# nrf54lm20a_enga_application register map
Vendor: Nordic Semiconductor; Series: nrf54l; File version: 1
CPU: CM33 r0p4, little endian, MPU, FPU, 3 interrupt priority bits, 270 interrupts, 4 SAU regions
Registers are 32-bit, read-write, reset 0x0 unless marked. A register's access mark holds for its fields unless they carry their own. Offsets are from the block's base; [hi:lo] are bit positions; lines under a group give offsets from that group; {n}, {i} and the like mark numbered series; 'fields as' and 'values as' point back to an identical list.

## GLOBAL_ECB00_NS — AES ECB Mode Encryption 0
Base 0x4004B000
Same registers: GLOBAL_ECB00_S 0x5004B000
0x00 TASKS_START wo — Start ECB block encrypt
  [0] TASKS_START
    1=Trigger task
0x04 TASKS_STOP wo — Abort a possible executing ECB operation
  [0] TASKS_STOP
    1=Trigger task
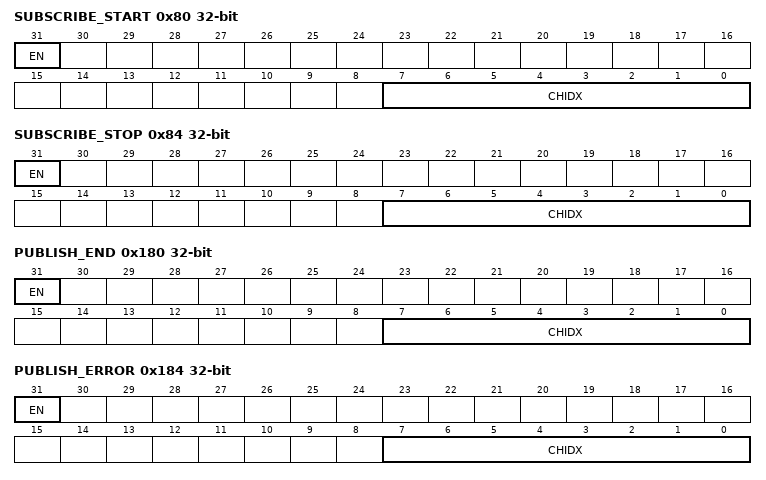
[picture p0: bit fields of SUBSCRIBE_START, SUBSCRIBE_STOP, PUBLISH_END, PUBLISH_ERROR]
0x80 SUBSCRIBE_START — Subscribe configuration for task START
  [31] EN
    0=Disabled (Disable subscription); 1=Enabled (Enable subscription)
  [7:0] CHIDX — DPPI channel that task START will subscribe to
0x84 SUBSCRIBE_STOP — Subscribe configuration for task STOP
  [31] EN
    values as SUBSCRIBE_START.EN
  [7:0] CHIDX — DPPI channel that task STOP will subscribe to
0x100 EVENTS_END — ECB block encrypt complete
  [0] EVENTS_END
    0=NotGenerated (Event not generated); 1=Generated (Event generated)
0x104 EVENTS_ERROR — ECB block encrypt aborted because of a STOP task or due to an error
  [0] EVENTS_ERROR
    values as EVENTS_END.EVENTS_END
0x180 PUBLISH_END — Publish configuration for event END
  [31] EN
    0=Disabled (Disable publishing); 1=Enabled (Enable publishing)
  [7:0] CHIDX — DPPI channel that event END will publish to
0x184 PUBLISH_ERROR — Publish configuration for event ERROR
  [31] EN
    values as PUBLISH_END.EN
  [7:0] CHIDX — DPPI channel that event ERROR will publish to
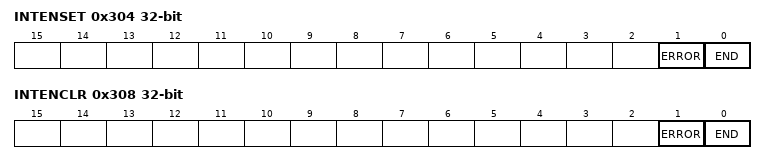
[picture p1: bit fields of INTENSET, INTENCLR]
0x304 INTENSET — Enable interrupt
  [1] ERROR — Write '1' to enable interrupt for event ERROR
    on read: 0=Disabled (Read: Disabled); 1=Enabled (Read: Enabled) | on write: 1=Set (Enable)
  [0] END — Write '1' to enable interrupt for event END
    values as ERROR
0x308 INTENCLR — Disable interrupt
  [1] ERROR — Write '1' to disable interrupt for event ERROR
    on read: 0=Disabled (Read: Disabled); 1=Enabled (Read: Enabled) | on write: 1=Clear (Disable)
  [0] END — Write '1' to disable interrupt for event END
    values as ERROR
0x400 ERRORSTATUS ro
  [2:0] ERRORSTATUS — Error status when the ERROR event is generated
    0=No errors have occurred; 1=PrematureInptrEnd (End of INPTR job list before data structure was read.); 2=PrematureOutptrEnd (End of OUTPTR job list before data structure was read.); 3=EncryptionTooSlow (Deprecated enumerator - Encryption aborted due to higher priority peripheral requesting or using the AES module.); 3=Aborted (Encryption aborted due to higher priority peripheral requesting or using the AES module.); 4=DmaError (Bus error during DMA access.)
0x510 KEY group — Unspecified
  {0x0+4j} VALUE[{j}] (j=0..3) wo — Description collection: 128-bit AES key
    [31:0] VALUE — AES 128-bit key value, bits (32*(n+1))-1 : (32*n)
0x530 IN group — IN EasyDMA channel
  0x00 PTR — Input pointer
    [31:0] PTR — Points to a job list containing unencrypted ECB data structure
0x538 OUT group — OUT EasyDMA channel
  0x00 PTR — Output pointer Points to a job list containing encrypted ECB data structure
    [31:0] PTR — Output pointer

## GLOBAL_GLITCHDET_S — Voltage glitch detectors
Base 0x5004E000
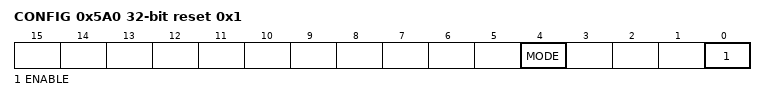
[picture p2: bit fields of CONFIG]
0x5A0 CONFIG reset 0x1 — Configuration for glitch detector
  [4] MODE — Glitch detector mode
    0=High pass filter mode; 1=Cap divider mode
  [0] ENABLE — Enable glitch detector
    0=Disable glitch detector; 1=Enable glitch detector

## GLOBAL_P2_NS — GPIO Port 0
Base 0x40050400
Same registers: GLOBAL_P1_NS 0x400D8200, GLOBAL_P3_NS 0x400D8600, GLOBAL_P0_NS 0x4010A000, GLOBAL_P2_S 0x50050400 (alternate view of GLOBAL_GPIOHSPADCTRL_S), GLOBAL_P1_S 0x500D8200, GLOBAL_P3_S 0x500D8600, GLOBAL_P0_S 0x5010A000
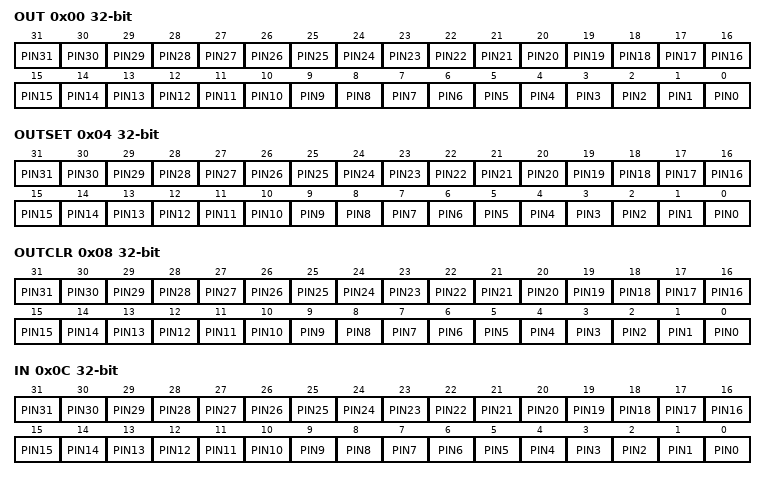
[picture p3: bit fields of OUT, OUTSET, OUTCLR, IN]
0x00 OUT — Write GPIO port
  [all] fields
    0=Low (Pin driver is low); 1=High (Pin driver is high)
  [n] PIN{n} (n=0..31)
0x04 OUTSET write-1-sets — Set individual bits in GPIO port
  [all] fields
    on read: 0=Low (Read: pin driver is low); 1=High (Read: pin driver is high) | on write: 1=Set (Write: writing a '1' sets the pin high; writing a '0' has no effect)
  [n] PIN{n} (n=0..31)
0x08 OUTCLR write-1-clears — Clear individual bits in GPIO port
  [all] fields
    on read: 0=Low (Read: pin driver is low); 1=High (Read: pin driver is high) | on write: 1=Clear (Write: writing a '1' sets the pin low; writing a '0' has no effect)
  [n] PIN{n} (n=0..31)
0x0C IN ro — Read GPIO port
  [all] fields
    0=Low (Pin input is low); 1=High (Pin input is high)
  [n] PIN{n} (n=0..31)
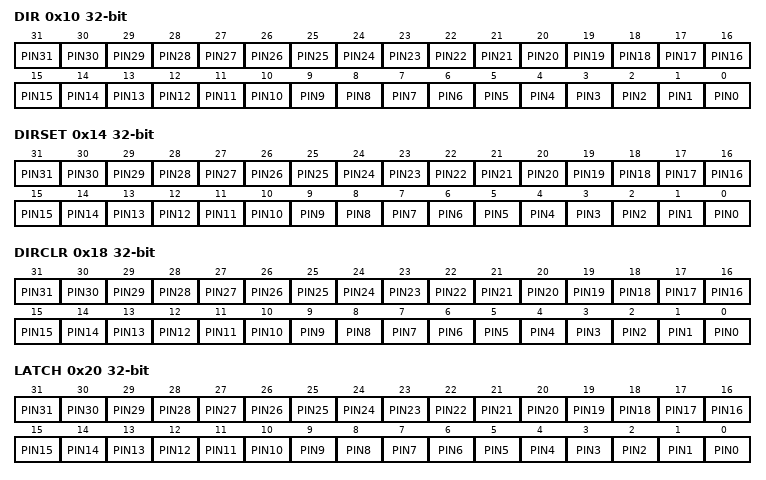
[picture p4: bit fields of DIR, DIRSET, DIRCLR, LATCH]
0x10 DIR — Direction of GPIO pins
  [all] fields
    0=Input (Pin set as input); 1=Output (Pin set as output)
  [n] PIN{n} (n=0..31)
0x14 DIRSET write-1-sets
  [all] fields
    on read: 0=Input (Read: pin set as input); 1=Output (Read: pin set as output) | on write: 1=Set (Write: writing a '1' sets pin to output; writing a '0' has no effect)
  [n] PIN{n} (n=0..31) — Set as output pin {n}
0x18 DIRCLR write-1-clears — DIR clear register
  [all] fields
    on read: 0=Input (Read: pin set as input); 1=Output (Read: pin set as output) | on write: 1=Clear (Write: writing a '1' sets pin to input; writing a '0' has no effect)
  [n] PIN{n} (n=0..31) — Set as input pin {n}
0x20 LATCH — Latch register indicating what GPIO pins that have met the criteria set in the PIN_CNF[n].SENSE registers
  [all] fields
    0=NotLatched (Criteria has not been met); 1=Latched (Criteria has been met)
  [n] PIN{n} (n=0..31) — Status on whether PIN{n} has met criteria set in PIN_CNF[{n}].SENSE register. Write '1' to clear.
0x24 DETECTMODE — Select between default DETECT signal behavior and LDETECT mode
  [0] DETECTMODE
    0=Default (DETECT directly connected to PIN DETECT signals); 1=LDETECT (Use the latched LDETECT behavior)
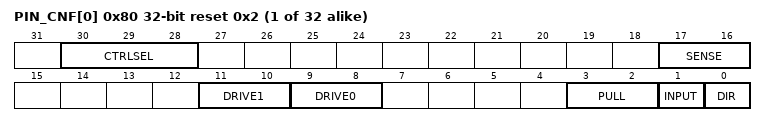
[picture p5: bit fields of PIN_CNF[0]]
{0x80+4i} PIN_CNF[{i}] (i=0..31) reset 0x2 — Description collection: Pin n configuration of GPIO pin
  [30:28] CTRLSEL — Select which module has direct control over this pin
    0=GPIO (GPIO or peripherals with PSEL registers); 1=VPR (VPR processor); 4=GRTC (GRTC peripheral)
  [17:16] SENSE — Pin sensing mechanism
    0=Disabled; 2=High (Sense for high level); 3=Low (Sense for low level)
  [11:10] DRIVE1 — Drive configuration for '1'
    0=S1 (Standard '1'); 1=H1 (High drive '1'); 2=D1 (Disconnect '1'(normally used for wired-or connections)); 3=E1 (Extra high drive '1')
  [9:8] DRIVE0 — Drive configuration for '0'
    0=S0 (Standard '0'); 1=H0 (High drive '0'); 2=D0 (Disconnect '0'(normally used for wired-or connections)); 3=E0 (Extra high drive '0')
  [3:2] PULL — Pull configuration
    0=Disabled (No pull); 1=Pull down on pin; 3=Pull up on pin
  [1] INPUT — Connect or disconnect input buffer
    0=Connect input buffer; 1=Disconnect input buffer
  [0] DIR — Pin direction. Same physical register as DIR register
    0=Input (Configure pin as an input pin); 1=Output (Configure pin as an output pin)
